VERSION ""

NS_ :

BS_:

BU_: VCU BMS CCU Monitor

BO_ 3221225472 VECTOR__INDEPENDENT_SIG_MSG: 0 Vector__XXX
 SG_ CCU2_1_Rsvd2 : 0|1@0+ (1,0) [0|1] "" Vector__XXX
 SG_ CCU2_2_Rsvd2 : 0|1@0+ (1,0) [0|1] "" Vector__XXX
 SG_ CCU2_0_Rsvd2 : 0|1@0+ (1,0) [0|1] "" Vector__XXX
 SG_ CCU2_3_Rsvd2 : 0|1@0+ (1,0) [0|1] "" Vector__XXX

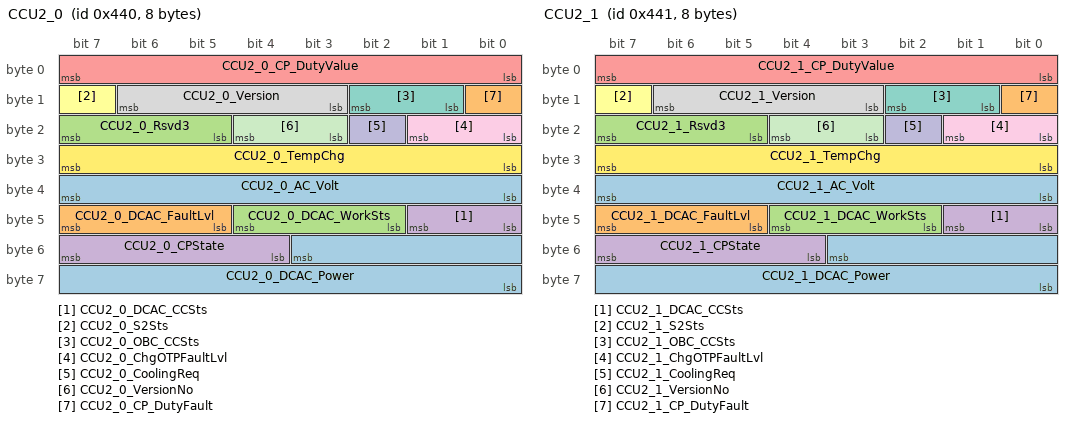
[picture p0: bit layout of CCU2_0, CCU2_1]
BO_ 1088 CCU2_0: 8 CCU
 SG_ CCU2_0_DCAC_Power : 51|12@0+ (1,0) [0|2047] "W"  BMS
 SG_ CCU2_0_DCAC_FaultLvl : 47|3@0+ (1,0) [0|3] ""  BMS
 SG_ CCU2_0_DCAC_WorkSts : 44|3@0+ (1,0) [0|7] ""  BMS
 SG_ CCU2_0_DCAC_CCSts : 41|2@0+ (1,0) [0|3] ""  BMS
 SG_ CCU2_0_CP_DutyValue : 7|8@0+ (1,0) [0|100] ""  BMS
 SG_ CCU2_0_S2Sts : 15|1@0+ (1,0) [0|1] ""  BMS
 SG_ CCU2_0_OBC_CCSts : 10|2@0+ (1,0) [0|3] ""  BMS
 SG_ CCU2_0_Version : 14|4@0+ (1,0) [0|3] ""  BMS
 SG_ CCU2_0_ChgOTPFaultLvl : 17|2@0+ (1,0) [0|3] ""  BMS
 SG_ CCU2_0_CoolingReq : 18|1@0+ (1,0) [0|1] ""  BMS
 SG_ CCU2_0_VersionNo : 20|2@0+ (1,0) [0|3] ""  BMS
 SG_ CCU2_0_TempChg : 31|8@0+ (1,-40) [-40|215] "C"  BMS
 SG_ CCU2_0_AC_Volt : 39|8@0+ (2,0) [0|510] "V"  BMS
 SG_ CCU2_0_CP_DutyFault : 8|1@0+ (1,0) [0|1] ""  BMS
 SG_ CCU2_0_Rsvd3 : 23|3@0+ (1,0) [0|7] ""  BMS
 SG_ CCU2_0_CPState : 55|4@0+ (1,0) [0|0] ""  BMS

BO_ 1089 CCU2_1: 8 CCU
 SG_ CCU2_1_DCAC_Power : 51|12@0+ (1,0) [0|2047] "W"  BMS
 SG_ CCU2_1_DCAC_FaultLvl : 47|3@0+ (1,0) [0|3] ""  BMS
 SG_ CCU2_1_DCAC_WorkSts : 44|3@0+ (1,0) [0|7] ""  BMS
 SG_ CCU2_1_DCAC_CCSts : 41|2@0+ (1,0) [0|3] ""  BMS
 SG_ CCU2_1_CP_DutyValue : 7|8@0+ (1,0) [0|100] ""  BMS
 SG_ CCU2_1_S2Sts : 15|1@0+ (1,0) [0|1] ""  BMS
 SG_ CCU2_1_OBC_CCSts : 10|2@0+ (1,0) [0|3] ""  BMS
 SG_ CCU2_1_Version : 14|4@0+ (1,0) [0|3] ""  BMS
 SG_ CCU2_1_ChgOTPFaultLvl : 17|2@0+ (1,0) [0|3] ""  BMS
 SG_ CCU2_1_CoolingReq : 18|1@0+ (1,0) [0|1] ""  BMS
 SG_ CCU2_1_VersionNo : 20|2@0+ (1,0) [0|3] ""  BMS
 SG_ CCU2_1_TempChg : 31|8@0+ (1,-40) [-40|215] "C"  BMS
 SG_ CCU2_1_AC_Volt : 39|8@0+ (2,0) [0|510] "V"  BMS
 SG_ CCU2_1_CP_DutyFault : 8|1@0+ (1,0) [0|1] ""  BMS
 SG_ CCU2_1_Rsvd3 : 23|3@0+ (1,0) [0|7] ""  BMS
 SG_ CCU2_1_CPState : 55|4@0+ (1,0) [0|0] ""  BMS

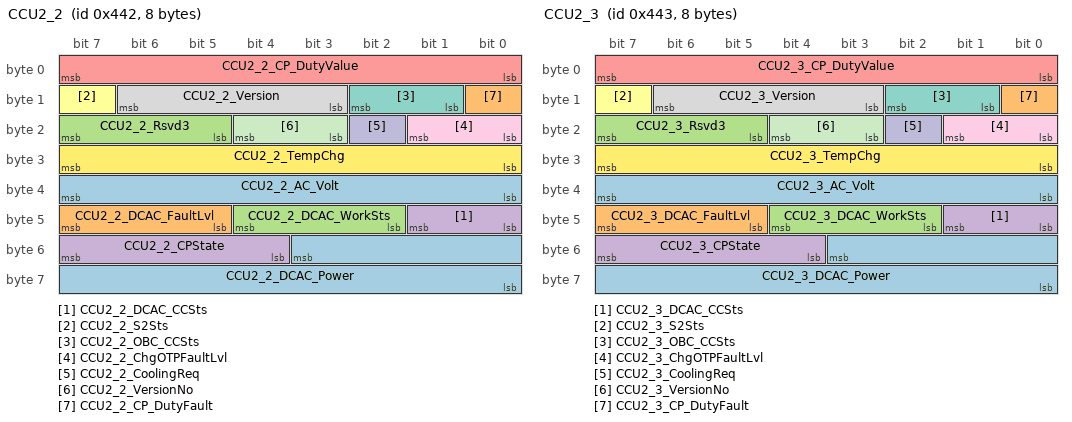
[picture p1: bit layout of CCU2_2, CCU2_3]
BO_ 1090 CCU2_2: 8 CCU
 SG_ CCU2_2_DCAC_Power : 51|12@0+ (1,0) [0|2047] "W"  BMS
 SG_ CCU2_2_DCAC_FaultLvl : 47|3@0+ (1,0) [0|3] ""  BMS
 SG_ CCU2_2_DCAC_WorkSts : 44|3@0+ (1,0) [0|7] ""  BMS
 SG_ CCU2_2_DCAC_CCSts : 41|2@0+ (1,0) [0|3] ""  BMS
 SG_ CCU2_2_CP_DutyValue : 7|8@0+ (1,0) [0|100] ""  BMS
 SG_ CCU2_2_S2Sts : 15|1@0+ (1,0) [0|1] ""  BMS
 SG_ CCU2_2_OBC_CCSts : 10|2@0+ (1,0) [0|3] ""  BMS
 SG_ CCU2_2_Version : 14|4@0+ (1,0) [0|3] ""  BMS
 SG_ CCU2_2_ChgOTPFaultLvl : 17|2@0+ (1,0) [0|3] ""  BMS
 SG_ CCU2_2_CoolingReq : 18|1@0+ (1,0) [0|1] ""  BMS
 SG_ CCU2_2_VersionNo : 20|2@0+ (1,0) [0|3] ""  BMS
 SG_ CCU2_2_TempChg : 31|8@0+ (1,-40) [-40|215] "C"  BMS
 SG_ CCU2_2_AC_Volt : 39|8@0+ (2,0) [0|510] "V"  BMS
 SG_ CCU2_2_CP_DutyFault : 8|1@0+ (1,0) [0|1] ""  BMS
 SG_ CCU2_2_Rsvd3 : 23|3@0+ (1,0) [0|7] ""  BMS
 SG_ CCU2_2_CPState : 55|4@0+ (1,0) [0|0] ""  BMS

BO_ 1091 CCU2_3: 8 CCU
 SG_ CCU2_3_DCAC_Power : 51|12@0+ (1,0) [0|2047] "W"  BMS
 SG_ CCU2_3_DCAC_FaultLvl : 47|3@0+ (1,0) [0|3] ""  BMS
 SG_ CCU2_3_DCAC_WorkSts : 44|3@0+ (1,0) [0|7] ""  BMS
 SG_ CCU2_3_DCAC_CCSts : 41|2@0+ (1,0) [0|3] ""  BMS
 SG_ CCU2_3_CP_DutyValue : 7|8@0+ (1,0) [0|100] ""  BMS
 SG_ CCU2_3_S2Sts : 15|1@0+ (1,0) [0|1] ""  BMS
 SG_ CCU2_3_OBC_CCSts : 10|2@0+ (1,0) [0|3] ""  BMS
 SG_ CCU2_3_Version : 14|4@0+ (1,0) [0|3] ""  BMS
 SG_ CCU2_3_ChgOTPFaultLvl : 17|2@0+ (1,0) [0|3] ""  BMS
 SG_ CCU2_3_CoolingReq : 18|1@0+ (1,0) [0|1] ""  BMS
 SG_ CCU2_3_VersionNo : 20|2@0+ (1,0) [0|3] ""  BMS
 SG_ CCU2_3_TempChg : 31|8@0+ (1,-40) [-40|215] "C"  BMS
 SG_ CCU2_3_AC_Volt : 39|8@0+ (2,0) [0|510] "V"  BMS
 SG_ CCU2_3_CP_DutyFault : 8|1@0+ (1,0) [0|1] ""  BMS
 SG_ CCU2_3_Rsvd3 : 23|3@0+ (1,0) [0|7] ""  BMS
 SG_ CCU2_3_CPState : 55|4@0+ (1,0) [0|0] ""  BMS

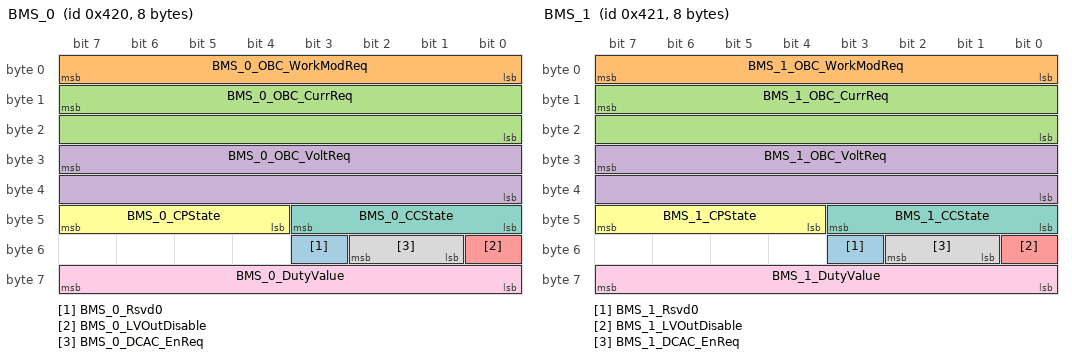
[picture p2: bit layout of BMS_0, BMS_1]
BO_ 1056 BMS_0: 8 BMS
 SG_ BMS_0_Rsvd0 : 51|1@0+ (1,0) [0|1] ""  CCU
 SG_ BMS_0_OBC_WorkModReq : 7|8@0+ (1,0) [0|4] ""  CCU
 SG_ BMS_0_OBC_CurrReq : 15|16@0+ (0.05,0) [0|400] "A"  CCU
 SG_ BMS_0_OBC_VoltReq : 31|16@0+ (0.05,0) [0|1000] "V"  CCU
 SG_ BMS_0_LVOutDisable : 48|1@0+ (1,0) [0|1] ""  CCU
 SG_ BMS_0_CPState : 47|4@0+ (1,0) [0|0] ""  CCU
 SG_ BMS_0_CCState : 43|4@0+ (1,0) [0|0] ""  CCU
 SG_ BMS_0_DCAC_EnReq : 50|2@0+ (1,0) [0|3] ""  CCU
 SG_ BMS_0_DutyValue : 63|8@0+ (1,0) [0|100] "" Vector__XXX

BO_ 1057 BMS_1: 8 BMS
 SG_ BMS_1_Rsvd0 : 51|1@0+ (1,0) [0|1] ""  CCU
 SG_ BMS_1_OBC_WorkModReq : 7|8@0+ (1,0) [0|4] ""  CCU
 SG_ BMS_1_OBC_CurrReq : 15|16@0+ (0.05,0) [0|400] "A"  CCU
 SG_ BMS_1_OBC_VoltReq : 31|16@0+ (0.05,0) [0|1000] "V"  CCU
 SG_ BMS_1_LVOutDisable : 48|1@0+ (1,0) [0|1] ""  CCU
 SG_ BMS_1_CPState : 47|4@0+ (1,0) [0|0] ""  CCU
 SG_ BMS_1_CCState : 43|4@0+ (1,0) [0|0] ""  CCU
 SG_ BMS_1_DCAC_EnReq : 50|2@0+ (1,0) [0|3] ""  CCU
 SG_ BMS_1_DutyValue : 63|8@0+ (1,0) [0|100] "" Vector__XXX

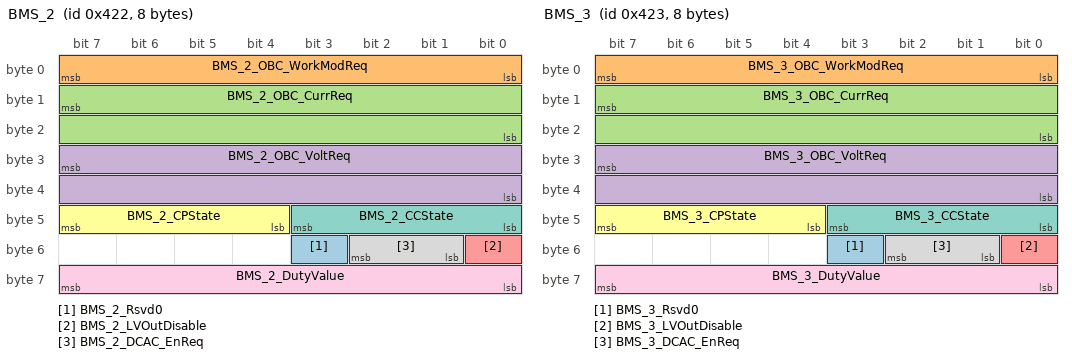
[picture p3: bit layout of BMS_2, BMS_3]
BO_ 1058 BMS_2: 8 BMS
 SG_ BMS_2_Rsvd0 : 51|1@0+ (1,0) [0|1] ""  CCU
 SG_ BMS_2_OBC_WorkModReq : 7|8@0+ (1,0) [0|4] ""  CCU
 SG_ BMS_2_OBC_CurrReq : 15|16@0+ (0.05,0) [0|400] "A"  CCU
 SG_ BMS_2_OBC_VoltReq : 31|16@0+ (0.05,0) [0|1000] "V"  CCU
 SG_ BMS_2_LVOutDisable : 48|1@0+ (1,0) [0|1] ""  CCU
 SG_ BMS_2_CPState : 47|4@0+ (1,0) [0|0] ""  CCU
 SG_ BMS_2_CCState : 43|4@0+ (1,0) [0|0] ""  CCU
 SG_ BMS_2_DCAC_EnReq : 50|2@0+ (1,0) [0|3] ""  CCU
 SG_ BMS_2_DutyValue : 63|8@0+ (1,0) [0|100] "" Vector__XXX

BO_ 1059 BMS_3: 8 BMS
 SG_ BMS_3_Rsvd0 : 51|1@0+ (1,0) [0|1] ""  CCU
 SG_ BMS_3_OBC_WorkModReq : 7|8@0+ (1,0) [0|4] ""  CCU
 SG_ BMS_3_OBC_CurrReq : 15|16@0+ (0.05,0) [0|400] "A"  CCU
 SG_ BMS_3_OBC_VoltReq : 31|16@0+ (0.05,0) [0|1000] "V"  CCU
 SG_ BMS_3_LVOutDisable : 48|1@0+ (1,0) [0|1] ""  CCU
 SG_ BMS_3_CPState : 47|4@0+ (1,0) [0|0] ""  CCU
 SG_ BMS_3_CCState : 43|4@0+ (1,0) [0|0] ""  CCU
 SG_ BMS_3_DCAC_EnReq : 50|2@0+ (1,0) [0|3] ""  CCU
 SG_ BMS_3_DutyValue : 63|8@0+ (1,0) [0|100] "" Vector__XXX

BO_ 1104 CCU3_0: 8 CCU
 SG_ CCU3_0_DCDC_OutputVolt : 7|8@0+ (0.1,0) [0|25.4] "V"  VCU
 SG_ CCU3_0_DCDC_OutputCurr : 15|8@0+ (1,0) [0|254] "A"  VCU
 SG_ CCU3_0_DCDC_InputVolt : 16|9@0+ (1,0) [0|510] "V"  VCU
 SG_ CCU3_0_DCDC_Temp : 39|8@0+ (1,-40) [-40|200] "oC"  VCU
 SG_ CCU3_0_DCDC_WorkSts : 41|2@0+ (1,0) [0|3] ""  VCU
 SG_ CCU3_0_DCDC_EnSts : 42|1@0+ (1,0) [0|1] ""  VCU
 SG_ CCU3_0_DCDC_DTC : 63|8@0+ (1,0) [0|255] ""  VCU
 SG_ CCU3_0_RollCnt : 46|4@0+ (1,0) [0|15] ""  VCU
 SG_ CCU3_0_DCDC_LVOVP : 48|1@0+ (1,0) [0|1] ""  VCU
 SG_ CCU3_0_DCDC_LVUVP : 49|1@0+ (1,0) [0|1] ""  VCU
 SG_ CCU3_0_DCDC_OTP : 50|1@0+ (1,0) [0|1] ""  VCU
 SG_ CCU3_0_DCDC_LVOCP : 51|1@0+ (1,0) [0|1] ""  VCU
 SG_ CCU3_0_DCDC_HVOVP : 52|1@0+ (1,0) [0|1] ""  VCU
 SG_ CCU3_0_DCDC_HVUVP : 53|1@0+ (1,0) [0|1] ""  VCU
 SG_ CCU3_0_DCDC_CANTimeOut : 54|1@0+ (1,0) [0|1] ""  VCU
 SG_ CCU3_0_DCDC_CoolRqt : 47|1@0+ (1,0) [0|1] ""  VCU
 SG_ CCU3_0_DCDC_ConvMode : 23|2@0+ (1,0) [0|3] ""  VCU

BO_ 1105 CCU3_1: 8 CCU
 SG_ CCU3_1_DCDC_OutputVolt : 7|8@0+ (0.1,0) [0|25.4] "V"  VCU
 SG_ CCU3_1_DCDC_OutputCurr : 15|8@0+ (1,0) [0|254] "A"  VCU
 SG_ CCU3_1_DCDC_InputVolt : 16|9@0+ (1,0) [0|510] "V"  VCU
 SG_ CCU3_1_DCDC_Temp : 39|8@0+ (1,-40) [-40|200] "oC"  VCU
 SG_ CCU3_1_DCDC_WorkSts : 41|2@0+ (1,0) [0|3] ""  VCU
 SG_ CCU3_1_DCDC_EnSts : 42|1@0+ (1,0) [0|1] ""  VCU
 SG_ CCU3_1_DCDC_DTC : 63|8@0+ (1,0) [0|255] ""  VCU
 SG_ CCU3_1_RollCnt : 46|4@0+ (1,0) [0|15] ""  VCU
 SG_ CCU3_1_DCDC_LVOVP : 48|1@0+ (1,0) [0|1] ""  VCU
 SG_ CCU3_1_DCDC_LVUVP : 49|1@0+ (1,0) [0|1] ""  VCU
 SG_ CCU3_1_DCDC_OTP : 50|1@0+ (1,0) [0|1] ""  VCU
 SG_ CCU3_1_DCDC_LVOCP : 51|1@0+ (1,0) [0|1] ""  VCU
 SG_ CCU3_1_DCDC_HVOVP : 52|1@0+ (1,0) [0|1] ""  VCU
 SG_ CCU3_1_DCDC_HVUVP : 53|1@0+ (1,0) [0|1] ""  VCU
 SG_ CCU3_1_DCDC_CANTimeOut : 54|1@0+ (1,0) [0|1] ""  VCU
 SG_ CCU3_1_DCDC_CoolRqt : 47|1@0+ (1,0) [0|1] ""  VCU
 SG_ CCU3_1_DCDC_ConvMode : 23|2@0+ (1,0) [0|3] ""  VCU

BO_ 1106 CCU3_2: 8 CCU
 SG_ CCU3_2_DCDC_OutputVolt : 7|8@0+ (0.1,0) [0|25.4] "V"  VCU
 SG_ CCU3_2_DCDC_OutputCurr : 15|8@0+ (1,0) [0|254] "A"  VCU
 SG_ CCU3_2_DCDC_InputVolt : 16|9@0+ (1,0) [0|510] "V"  VCU
 SG_ CCU3_2_DCDC_Temp : 39|8@0+ (1,-40) [-40|200] "oC"  VCU
 SG_ CCU3_2_DCDC_WorkSts : 41|2@0+ (1,0) [0|3] ""  VCU
 SG_ CCU3_2_DCDC_EnSts : 42|1@0+ (1,0) [0|1] ""  VCU
 SG_ CCU3_2_DCDC_DTC : 63|8@0+ (1,0) [0|255] ""  VCU
 SG_ CCU3_2_RollCnt : 46|4@0+ (1,0) [0|15] ""  VCU
 SG_ CCU3_2_DCDC_LVOVP : 48|1@0+ (1,0) [0|1] ""  VCU
 SG_ CCU3_2_DCDC_LVUVP : 49|1@0+ (1,0) [0|1] ""  VCU
 SG_ CCU3_2_DCDC_OTP : 50|1@0+ (1,0) [0|1] ""  VCU
 SG_ CCU3_2_DCDC_LVOCP : 51|1@0+ (1,0) [0|1] ""  VCU
 SG_ CCU3_2_DCDC_HVOVP : 52|1@0+ (1,0) [0|1] ""  VCU
 SG_ CCU3_2_DCDC_HVUVP : 53|1@0+ (1,0) [0|1] ""  VCU
 SG_ CCU3_2_DCDC_CANTimeOut : 54|1@0+ (1,0) [0|1] ""  VCU
 SG_ CCU3_2_DCDC_CoolRqt : 47|1@0+ (1,0) [0|1] ""  VCU
 SG_ CCU3_2_DCDC_ConvMode : 23|2@0+ (1,0) [0|3] ""  VCU

BO_ 1107 CCU3_3: 8 CCU
 SG_ CCU3_3_DCDC_OutputVolt : 7|8@0+ (0.1,0) [0|25.4] "V"  VCU
 SG_ CCU3_3_DCDC_OutputCurr : 15|8@0+ (1,0) [0|254] "A"  VCU
 SG_ CCU3_3_DCDC_InputVolt : 16|9@0+ (1,0) [0|510] "V"  VCU
 SG_ CCU3_3_DCDC_Temp : 39|8@0+ (1,-40) [-40|200] "oC"  VCU
 SG_ CCU3_3_DCDC_WorkSts : 41|2@0+ (1,0) [0|3] ""  VCU
 SG_ CCU3_3_DCDC_EnSts : 42|1@0+ (1,0) [0|1] ""  VCU
 SG_ CCU3_3_DCDC_DTC : 63|8@0+ (1,0) [0|255] ""  VCU
 SG_ CCU3_3_RollCnt : 46|4@0+ (1,0) [0|15] ""  VCU
 SG_ CCU3_3_DCDC_LVOVP : 48|1@0+ (1,0) [0|1] ""  VCU
 SG_ CCU3_3_DCDC_LVUVP : 49|1@0+ (1,0) [0|1] ""  VCU
 SG_ CCU3_3_DCDC_OTP : 50|1@0+ (1,0) [0|1] ""  VCU
 SG_ CCU3_3_DCDC_LVOCP : 51|1@0+ (1,0) [0|1] ""  VCU
 SG_ CCU3_3_DCDC_HVOVP : 52|1@0+ (1,0) [0|1] ""  VCU
 SG_ CCU3_3_DCDC_HVUVP : 53|1@0+ (1,0) [0|1] ""  VCU
 SG_ CCU3_3_DCDC_CANTimeOut : 54|1@0+ (1,0) [0|1] ""  VCU
 SG_ CCU3_3_DCDC_CoolRqt : 47|1@0+ (1,0) [0|1] ""  VCU
 SG_ CCU3_3_DCDC_ConvMode : 23|2@0+ (1,0) [0|3] ""  VCU

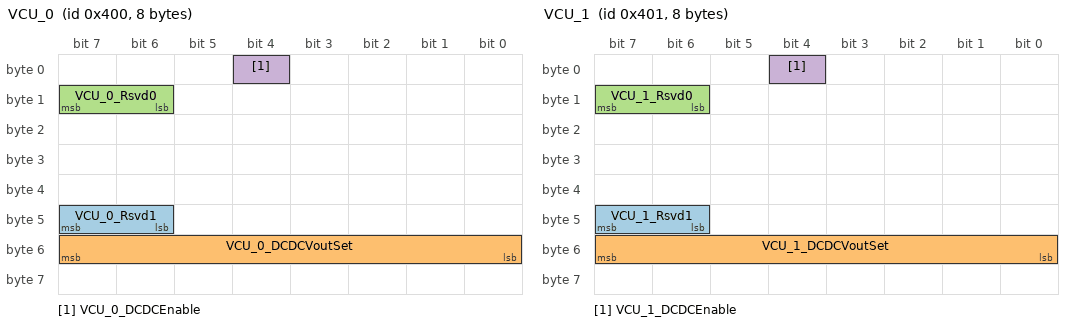
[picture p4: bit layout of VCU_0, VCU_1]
BO_ 1024 VCU_0: 8 VCU
 SG_ VCU_0_Rsvd1 : 47|2@0+ (1,0) [0|3] ""  CCU
 SG_ VCU_0_DCDCVoutSet : 55|8@0+ (0.1,0) [0|20] "V"  CCU
 SG_ VCU_0_Rsvd0 : 15|2@0+ (1,0) [0|1] ""  CCU
 SG_ VCU_0_DCDCEnable : 4|1@0+ (1,0) [0|1] ""  CCU

BO_ 1025 VCU_1: 8 VCU
 SG_ VCU_1_Rsvd1 : 47|2@0+ (1,0) [0|3] ""  CCU
 SG_ VCU_1_DCDCVoutSet : 55|8@0+ (0.1,0) [0|20] "V"  CCU
 SG_ VCU_1_Rsvd0 : 15|2@0+ (1,0) [0|1] ""  CCU
 SG_ VCU_1_DCDCEnable : 4|1@0+ (1,0) [0|1] ""  CCU

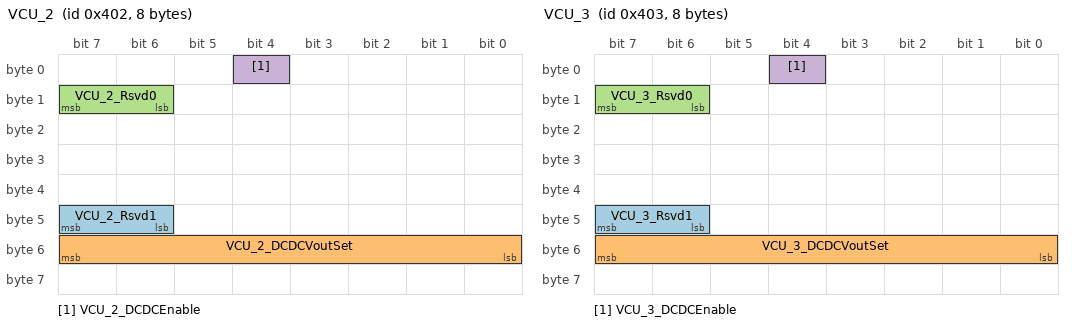
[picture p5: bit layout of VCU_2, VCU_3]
BO_ 1026 VCU_2: 8 VCU
 SG_ VCU_2_Rsvd1 : 47|2@0+ (1,0) [0|3] ""  CCU
 SG_ VCU_2_DCDCVoutSet : 55|8@0+ (0.1,0) [0|20] "V"  CCU
 SG_ VCU_2_Rsvd0 : 15|2@0+ (1,0) [0|1] ""  CCU
 SG_ VCU_2_DCDCEnable : 4|1@0+ (1,0) [0|1] ""  CCU

BO_ 1027 VCU_3: 8 VCU
 SG_ VCU_3_Rsvd1 : 47|2@0+ (1,0) [0|3] ""  CCU
 SG_ VCU_3_DCDCVoutSet : 55|8@0+ (0.1,0) [0|20] "V"  CCU
 SG_ VCU_3_Rsvd0 : 15|2@0+ (1,0) [0|1] ""  CCU
 SG_ VCU_3_DCDCEnable : 4|1@0+ (1,0) [0|1] ""  CCU

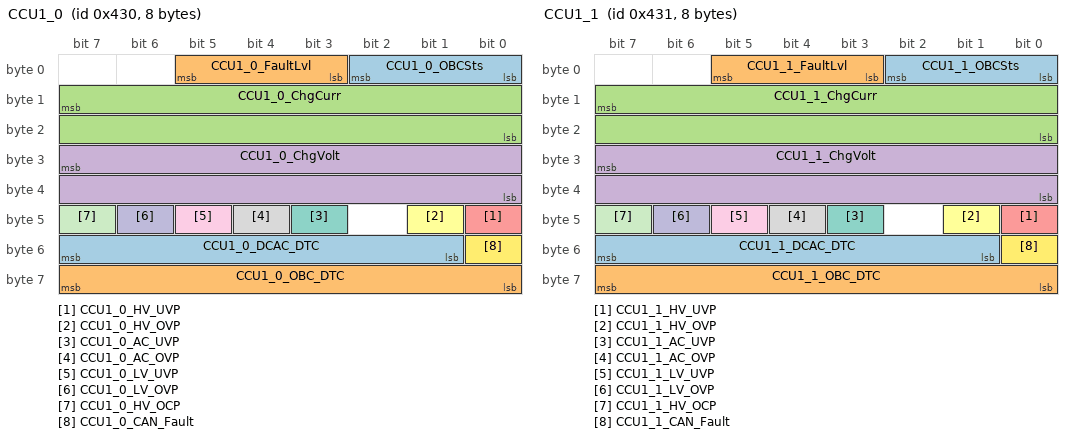
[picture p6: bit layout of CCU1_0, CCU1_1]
BO_ 1072 CCU1_0: 8 CCU
 SG_ CCU1_0_OBCSts : 2|3@0+ (1,0) [0|7] ""  BMS
 SG_ CCU1_0_FaultLvl : 5|3@0+ (1,0) [0|7] ""  BMS
 SG_ CCU1_0_ChgCurr : 15|16@0+ (0.05,0) [0|400] "A"  BMS
 SG_ CCU1_0_ChgVolt : 31|16@0+ (0.05,0) [0|1000] "V"  BMS
 SG_ CCU1_0_HV_UVP : 40|1@0+ (1,0) [0|1] ""  BMS
 SG_ CCU1_0_HV_OVP : 41|1@0+ (1,0) [0|1] ""  BMS
 SG_ CCU1_0_AC_UVP : 43|1@0+ (1,0) [0|1] ""  BMS
 SG_ CCU1_0_AC_OVP : 44|1@0+ (1,0) [0|1] ""  BMS
 SG_ CCU1_0_LV_UVP : 45|1@0+ (1,0) [0|1] ""  BMS
 SG_ CCU1_0_LV_OVP : 46|1@0+ (1,0) [0|1] ""  BMS
 SG_ CCU1_0_HV_OCP : 47|1@0+ (1,0) [0|1] ""  BMS
 SG_ CCU1_0_CAN_Fault : 48|1@0+ (1,0) [0|1] ""  BMS
 SG_ CCU1_0_DCAC_DTC : 55|7@0+ (1,0) [0|1] ""  BMS
 SG_ CCU1_0_OBC_DTC : 63|8@0+ (1,0) [0|0] ""  BMS

BO_ 1073 CCU1_1: 8 CCU
 SG_ CCU1_1_OBCSts : 2|3@0+ (1,0) [0|7] ""  BMS
 SG_ CCU1_1_FaultLvl : 5|3@0+ (1,0) [0|7] ""  BMS
 SG_ CCU1_1_ChgCurr : 15|16@0+ (0.05,0) [0|400] "A"  BMS
 SG_ CCU1_1_ChgVolt : 31|16@0+ (0.05,0) [0|1000] "V"  BMS
 SG_ CCU1_1_HV_UVP : 40|1@0+ (1,0) [0|1] ""  BMS
 SG_ CCU1_1_HV_OVP : 41|1@0+ (1,0) [0|1] ""  BMS
 SG_ CCU1_1_AC_UVP : 43|1@0+ (1,0) [0|1] ""  BMS
 SG_ CCU1_1_AC_OVP : 44|1@0+ (1,0) [0|1] ""  BMS
 SG_ CCU1_1_LV_UVP : 45|1@0+ (1,0) [0|1] ""  BMS
 SG_ CCU1_1_LV_OVP : 46|1@0+ (1,0) [0|1] ""  BMS
 SG_ CCU1_1_HV_OCP : 47|1@0+ (1,0) [0|1] ""  BMS
 SG_ CCU1_1_CAN_Fault : 48|1@0+ (1,0) [0|1] ""  BMS
 SG_ CCU1_1_DCAC_DTC : 55|7@0+ (1,0) [0|1] ""  BMS
 SG_ CCU1_1_OBC_DTC : 63|8@0+ (1,0) [0|0] ""  BMS

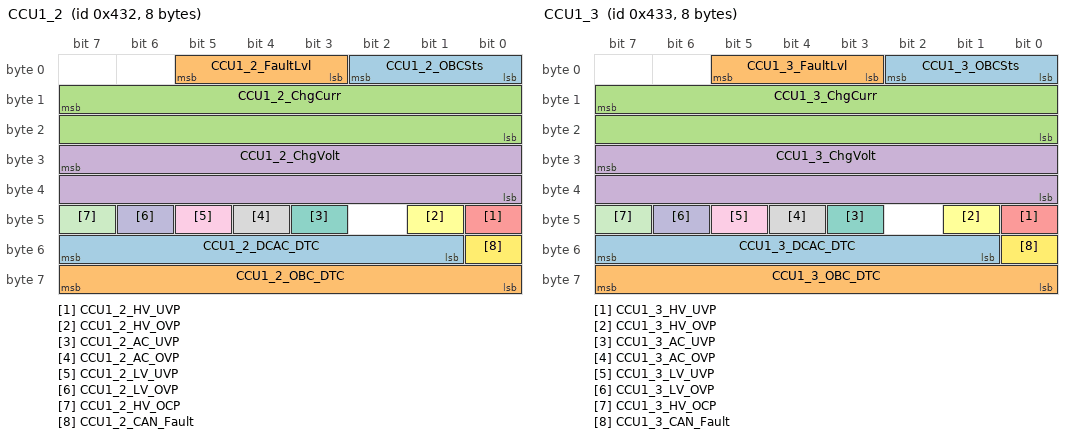
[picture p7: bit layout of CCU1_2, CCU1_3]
BO_ 1074 CCU1_2: 8 CCU
 SG_ CCU1_2_OBCSts : 2|3@0+ (1,0) [0|7] ""  BMS
 SG_ CCU1_2_FaultLvl : 5|3@0+ (1,0) [0|7] ""  BMS
 SG_ CCU1_2_ChgCurr : 15|16@0+ (0.05,0) [0|400] "A"  BMS
 SG_ CCU1_2_ChgVolt : 31|16@0+ (0.05,0) [0|1000] "V"  BMS
 SG_ CCU1_2_HV_UVP : 40|1@0+ (1,0) [0|1] ""  BMS
 SG_ CCU1_2_HV_OVP : 41|1@0+ (1,0) [0|1] ""  BMS
 SG_ CCU1_2_AC_UVP : 43|1@0+ (1,0) [0|1] ""  BMS
 SG_ CCU1_2_AC_OVP : 44|1@0+ (1,0) [0|1] ""  BMS
 SG_ CCU1_2_LV_UVP : 45|1@0+ (1,0) [0|1] ""  BMS
 SG_ CCU1_2_LV_OVP : 46|1@0+ (1,0) [0|1] ""  BMS
 SG_ CCU1_2_HV_OCP : 47|1@0+ (1,0) [0|1] ""  BMS
 SG_ CCU1_2_CAN_Fault : 48|1@0+ (1,0) [0|1] ""  BMS
 SG_ CCU1_2_DCAC_DTC : 55|7@0+ (1,0) [0|1] ""  BMS
 SG_ CCU1_2_OBC_DTC : 63|8@0+ (1,0) [0|0] ""  BMS

BO_ 1075 CCU1_3: 8 CCU
 SG_ CCU1_3_OBCSts : 2|3@0+ (1,0) [0|7] ""  BMS
 SG_ CCU1_3_FaultLvl : 5|3@0+ (1,0) [0|7] ""  BMS
 SG_ CCU1_3_ChgCurr : 15|16@0+ (0.05,0) [0|400] "A"  BMS
 SG_ CCU1_3_ChgVolt : 31|16@0+ (0.05,0) [0|1000] "V"  BMS
 SG_ CCU1_3_HV_UVP : 40|1@0+ (1,0) [0|1] ""  BMS
 SG_ CCU1_3_HV_OVP : 41|1@0+ (1,0) [0|1] ""  BMS
 SG_ CCU1_3_AC_UVP : 43|1@0+ (1,0) [0|1] ""  BMS
 SG_ CCU1_3_AC_OVP : 44|1@0+ (1,0) [0|1] ""  BMS
 SG_ CCU1_3_LV_UVP : 45|1@0+ (1,0) [0|1] ""  BMS
 SG_ CCU1_3_LV_OVP : 46|1@0+ (1,0) [0|1] ""  BMS
 SG_ CCU1_3_HV_OCP : 47|1@0+ (1,0) [0|1] ""  BMS
 SG_ CCU1_3_CAN_Fault : 48|1@0+ (1,0) [0|1] ""  BMS
 SG_ CCU1_3_DCAC_DTC : 55|7@0+ (1,0) [0|1] ""  BMS
 SG_ CCU1_3_OBC_DTC : 63|8@0+ (1,0) [0|0] ""  BMS

BO_ 1280 CaliIDTX_0: 8 Monitor
 SG_ CaliIDTX_0 : 7|64@0+ (1,0) [0|0] ""  CCU

BO_ 1281 CaliIDTX_1: 8 Monitor
 SG_ CaliIDTX_1 : 7|64@0+ (1,0) [0|0] ""  CCU

BO_ 1282 CaliIDTX_2: 8 Monitor
 SG_ CaliIDTX_2 : 7|64@0+ (1,0) [0|0] ""  CCU

BO_ 1283 CaliIDTX_3: 8 Monitor
 SG_ CaliIDTX_3 : 7|64@0+ (1,0) [0|0] ""  CCU

BO_ 1296 CaliIDRX: 8 CCU
 SG_ CaliIDR_0 : 7|64@0+ (1,0) [0|0] ""  Monitor

BO_ 1297 CaliIDRX: 8 CCU
 SG_ CaliIDRX_1 : 7|64@0+ (1,0) [0|0] ""  Monitor

BO_ 1298 CaliIDRX: 8 CCU
 SG_ CaliIDRX_2 : 7|64@0+ (1,0) [0|0] ""  Monitor

BO_ 1299 CaliIDRX: 8 CCU
 SG_ CaliIDRX_3 : 7|64@0+ (1,0) [0|0] ""  Monitor

CM_ BO_ 3221225472 "This is a message for not used signals, created by Vector CANdb++ DBC OLE DB Provider.";
CM_ SG_ 3221225472 CCU2_1_Rsvd2 "保留
(Reserved)";
CM_ SG_ 3221225472 CCU2_2_Rsvd2 "保留
(Reserved)";
CM_ SG_ 3221225472 CCU2_0_Rsvd2 "保留
(Reserved)";
CM_ SG_ 3221225472 CCU2_3_Rsvd2 "保留
(Reserved)";
CM_ SG_ 1088 CCU2_0_DCAC_Power "DCAC输出功率
(DCAC output power)";
CM_ SG_ 1088 CCU2_0_DCAC_FaultLvl "DCAC故障等级
(DCAC fault level)";
CM_ SG_ 1088 CCU2_0_DCAC_WorkSts "DCAC工作状态
(DCAC work status)";
CM_ SG_ 1088 CCU2_0_DCAC_CCSts "放电CC连接状态
(CC connect status in DCAC mode)";
CM_ SG_ 1088 CCU2_0_CP_DutyValue "CP占空比数值
(CP duty value)";
CM_ SG_ 1088 CCU2_0_S2Sts "S2开关状态
(S2 switch status)";
CM_ SG_ 1088 CCU2_0_OBC_CCSts "充电CC连接状态
(CC connect status in OBC mode)";
CM_ SG_ 1088 CCU2_0_ChgOTPFaultLvl "充电机过温
(Charge over temperature protection)";
CM_ SG_ 1088 CCU2_0_CoolingReq "充电机冷却请求
(Charger cool request)";
CM_ SG_ 1088 CCU2_0_VersionNo "软件版本序号
（Version No）";
CM_ SG_ 1088 CCU2_0_TempChg "充电机温度
(Charger temperature)";
CM_ SG_ 1088 CCU2_0_AC_Volt "AC电压(AC Volt)";
CM_ SG_ 1088 CCU2_0_CP_DutyFault "CP占空比异常
(CP duty abnormal)";
CM_ SG_ 1088 CCU2_0_CPState "CP状态
(CP state)";
CM_ SG_ 1089 CCU2_1_DCAC_Power "DCAC输出功率
(DCAC output power)";
CM_ SG_ 1089 CCU2_1_DCAC_FaultLvl "DCAC故障等级
(DCAC fault level)";
CM_ SG_ 1089 CCU2_1_DCAC_WorkSts "DCAC工作状态
(DCAC work status)";
CM_ SG_ 1089 CCU2_1_DCAC_CCSts "放电CC连接状态
(CC connect status in DCAC mode)";
CM_ SG_ 1089 CCU2_1_CP_DutyValue "CP占空比数值
(CP duty value)";
CM_ SG_ 1089 CCU2_1_S2Sts "S2开关状态
(S2 switch status)";
CM_ SG_ 1089 CCU2_1_OBC_CCSts "充电CC连接状态
(CC connect status in OBC mode)";
CM_ SG_ 1089 CCU2_1_ChgOTPFaultLvl "充电机过温
(Charge over temperature protection)";
CM_ SG_ 1089 CCU2_1_CoolingReq "充电机冷却请求
(Charger cool request)";
CM_ SG_ 1089 CCU2_1_VersionNo "软件版本序号
（Version No）";
CM_ SG_ 1089 CCU2_1_TempChg "充电机温度
(Charger temperature)";
CM_ SG_ 1089 CCU2_1_AC_Volt "AC电压(AC Volt)";
CM_ SG_ 1089 CCU2_1_CP_DutyFault "CP占空比异常
(CP duty abnormal)";
CM_ SG_ 1089 CCU2_1_CPState "CP状态
(CP state)";
CM_ SG_ 1090 CCU2_2_DCAC_Power "DCAC输出功率
(DCAC output power)";
CM_ SG_ 1090 CCU2_2_DCAC_FaultLvl "DCAC故障等级
(DCAC fault level)";
CM_ SG_ 1090 CCU2_2_DCAC_WorkSts "DCAC工作状态
(DCAC work status)";
CM_ SG_ 1090 CCU2_2_DCAC_CCSts "放电CC连接状态
(CC connect status in DCAC mode)";
CM_ SG_ 1090 CCU2_2_CP_DutyValue "CP占空比数值
(CP duty value)";
CM_ SG_ 1090 CCU2_2_S2Sts "S2开关状态
(S2 switch status)";
CM_ SG_ 1090 CCU2_2_OBC_CCSts "充电CC连接状态
(CC connect status in OBC mode)";
CM_ SG_ 1090 CCU2_2_ChgOTPFaultLvl "充电机过温
(Charge over temperature protection)";
CM_ SG_ 1090 CCU2_2_CoolingReq "充电机冷却请求
(Charger cool request)";
CM_ SG_ 1090 CCU2_2_VersionNo "软件版本序号
（Version No）";
CM_ SG_ 1090 CCU2_2_TempChg "充电机温度
(Charger temperature)";
CM_ SG_ 1090 CCU2_2_AC_Volt "AC电压(AC Volt)";
CM_ SG_ 1090 CCU2_2_CP_DutyFault "CP占空比异常
(CP duty abnormal)";
CM_ SG_ 1090 CCU2_2_CPState "CP状态
(CP state)";
CM_ SG_ 1091 CCU2_3_DCAC_Power "DCAC输出功率
(DCAC output power)";
CM_ SG_ 1091 CCU2_3_DCAC_FaultLvl "DCAC故障等级
(DCAC fault level)";
CM_ SG_ 1091 CCU2_3_DCAC_WorkSts "DCAC工作状态
(DCAC work status)";
CM_ SG_ 1091 CCU2_3_DCAC_CCSts "放电CC连接状态
(CC connect status in DCAC mode)";
CM_ SG_ 1091 CCU2_3_CP_DutyValue "CP占空比数值
(CP duty value)";
CM_ SG_ 1091 CCU2_3_S2Sts "S2开关状态
(S2 switch status)";
CM_ SG_ 1091 CCU2_3_OBC_CCSts "充电CC连接状态
(CC connect status in OBC mode)";
CM_ SG_ 1091 CCU2_3_ChgOTPFaultLvl "充电机过温
(Charge over temperature protection)";
CM_ SG_ 1091 CCU2_3_CoolingReq "充电机冷却请求
(Charger cool request)";
CM_ SG_ 1091 CCU2_3_VersionNo "软件版本序号
（Version No）";
CM_ SG_ 1091 CCU2_3_TempChg "充电机温度
(Charger temperature)";
CM_ SG_ 1091 CCU2_3_AC_Volt "AC电压(AC Volt)";
CM_ SG_ 1091 CCU2_3_CP_DutyFault "CP占空比异常
(CP duty abnormal)";
CM_ SG_ 1091 CCU2_3_CPState "CP状态
(CP state)";
CM_ SG_ 1056 BMS_0_Rsvd0 "Reserved,all value keep 0.";
CM_ SG_ 1056 BMS_0_OBC_WorkModReq "BMS请求工作模式
(BMS request work mode)";
CM_ SG_ 1056 BMS_0_OBC_CurrReq "BMS请求充电机输出充电电流值
(OBC output current point setting)";
CM_ SG_ 1056 BMS_0_OBC_VoltReq "BMS请求充电机输出充电电压值
(OBC output voltage point setting)";
CM_ SG_ 1056 BMS_0_LVOutDisable "BMS请求低压停止输出请求
(BMS request DCDC stop output)";
CM_ SG_ 1056 BMS_0_CPState "CP状态
(CP state)";
CM_ SG_ 1056 BMS_0_CCState "CC状态
(CC state)";
CM_ SG_ 1056 BMS_0_DCAC_EnReq "BMS请求DCAC输出
(BMS enable DCAC output)";
CM_ SG_ 1056 BMS_0_DutyValue "CP占空比数值
(CP duty value)";
CM_ SG_ 1057 BMS_1_Rsvd0 "Reserved,all value keep 0.";
CM_ SG_ 1057 BMS_1_OBC_WorkModReq "BMS请求工作模式
(BMS request work mode)";
CM_ SG_ 1057 BMS_1_OBC_CurrReq "BMS请求充电机输出充电电流值
(OBC output current point setting)";
CM_ SG_ 1057 BMS_1_OBC_VoltReq "BMS请求充电机输出充电电压值
(OBC output voltage point setting)";
CM_ SG_ 1057 BMS_1_LVOutDisable "BMS请求低压停止输出请求
(BMS request DCDC stop output)";
CM_ SG_ 1057 BMS_1_CPState "CP状态
(CP state)";
CM_ SG_ 1057 BMS_1_CCState "CC状态
(CC state)";
CM_ SG_ 1057 BMS_1_DCAC_EnReq "BMS请求DCAC输出
(BMS enable DCAC output)";
CM_ SG_ 1057 BMS_1_DutyValue "CP占空比数值
(CP duty value)";
CM_ SG_ 1058 BMS_2_Rsvd0 "Reserved,all value keep 0.";
CM_ SG_ 1058 BMS_2_OBC_WorkModReq "BMS请求工作模式
(BMS request work mode)";
CM_ SG_ 1058 BMS_2_OBC_CurrReq "BMS请求充电机输出充电电流值
(OBC output current point setting)";
CM_ SG_ 1058 BMS_2_OBC_VoltReq "BMS请求充电机输出充电电压值
(OBC output voltage point setting)";
CM_ SG_ 1058 BMS_2_LVOutDisable "BMS请求低压停止输出请求
(BMS request DCDC stop output)";
CM_ SG_ 1058 BMS_2_CPState "CP状态
(CP state)";
CM_ SG_ 1058 BMS_2_CCState "CC状态
(CC state)";
CM_ SG_ 1058 BMS_2_DCAC_EnReq "BMS请求DCAC输出
(BMS enable DCAC output)";
CM_ SG_ 1058 BMS_2_DutyValue "CP占空比数值
(CP duty value)";
CM_ SG_ 1059 BMS_3_Rsvd0 "Reserved,all value keep 0.";
CM_ SG_ 1059 BMS_3_OBC_WorkModReq "BMS请求工作模式
(BMS request work mode)";
CM_ SG_ 1059 BMS_3_OBC_CurrReq "BMS请求充电机输出充电电流值
(OBC output current point setting)";
CM_ SG_ 1059 BMS_3_OBC_VoltReq "BMS请求充电机输出充电电压值
(OBC output voltage point setting)";
CM_ SG_ 1059 BMS_3_LVOutDisable "BMS请求低压停止输出请求
(BMS request DCDC stop output)";
CM_ SG_ 1059 BMS_3_CPState "CP状态
(CP state)";
CM_ SG_ 1059 BMS_3_CCState "CC状态
(CC state)";
CM_ SG_ 1059 BMS_3_DCAC_EnReq "BMS请求DCAC输出
(BMS enable DCAC output)";
CM_ SG_ 1059 BMS_3_DutyValue "CP占空比数值
(CP duty value)";
CM_ SG_ 1104 CCU3_0_DCDC_OutputVolt "DCDC输出电压
(DCDC output voltage)";
CM_ SG_ 1104 CCU3_0_DCDC_OutputCurr "DCDC输出电流
(DCDC output current)";
CM_ SG_ 1104 CCU3_0_DCDC_InputVolt "DCDC输入电压
(DCDC input voltage)";
CM_ SG_ 1104 CCU3_0_DCDC_Temp "DCDC温度
(DCDC temperature)";
CM_ SG_ 1104 CCU3_0_DCDC_WorkSts "DCDC工作状态
(DCDC work status)";
CM_ SG_ 1104 CCU3_0_DCDC_EnSts "DCDC使能状态反馈
(DCDC output enable status feedback)";
CM_ SG_ 1104 CCU3_0_DCDC_DTC "DCDC故障
(DCDC DTC)";
CM_ SG_ 1104 CCU3_0_RollCnt "Rolling counter.";
CM_ SG_ 1104 CCU3_0_DCDC_LVOVP "DCDC输出过压
(DCDC output over voltage)";
CM_ SG_ 1104 CCU3_0_DCDC_LVUVP "DCDC输出欠压
(DCDC output under voltage)";
CM_ SG_ 1104 CCU3_0_DCDC_OTP "DCDC过温故障
(DCDC over temperature fault)";
CM_ SG_ 1104 CCU3_0_DCDC_LVOCP "DCDC输出过流
(DCDC output over current fault)";
CM_ SG_ 1104 CCU3_0_DCDC_HVOVP "DCDC输入过压
(DCDC input over voltage)";
CM_ SG_ 1104 CCU3_0_DCDC_HVUVP "DCDC输入欠压
(DCDC input under voltage)";
CM_ SG_ 1104 CCU3_0_DCDC_CANTimeOut "DCDC通讯超时
(DCDC CAN communication time-out)";
CM_ SG_ 1104 CCU3_0_DCDC_CoolRqt "DCDC冷却请求
(DCDC cool request)";
CM_ SG_ 1104 CCU3_0_DCDC_ConvMode "DCDC功率转换模式
(DCDC power conversion mode)";
CM_ SG_ 1105 CCU3_1_DCDC_OutputVolt "DCDC输出电压
(DCDC output voltage)";
CM_ SG_ 1105 CCU3_1_DCDC_OutputCurr "DCDC输出电流
(DCDC output current)";
CM_ SG_ 1105 CCU3_1_DCDC_InputVolt "DCDC输入电压
(DCDC input voltage)";
CM_ SG_ 1105 CCU3_1_DCDC_Temp "DCDC温度
(DCDC temperature)";
CM_ SG_ 1105 CCU3_1_DCDC_WorkSts "DCDC工作状态
(DCDC work status)";
CM_ SG_ 1105 CCU3_1_DCDC_EnSts "DCDC使能状态反馈
(DCDC output enable status feedback)";
CM_ SG_ 1105 CCU3_1_DCDC_DTC "DCDC故障
(DCDC DTC)";
CM_ SG_ 1105 CCU3_1_RollCnt "Rolling counter.";
CM_ SG_ 1105 CCU3_1_DCDC_LVOVP "DCDC输出过压
(DCDC output over voltage)";
CM_ SG_ 1105 CCU3_1_DCDC_LVUVP "DCDC输出欠压
(DCDC output under voltage)";
CM_ SG_ 1105 CCU3_1_DCDC_OTP "DCDC过温故障
(DCDC over temperature fault)";
CM_ SG_ 1105 CCU3_1_DCDC_LVOCP "DCDC输出过流
(DCDC output over current fault)";
CM_ SG_ 1105 CCU3_1_DCDC_HVOVP "DCDC输入过压
(DCDC input over voltage)";
CM_ SG_ 1105 CCU3_1_DCDC_HVUVP "DCDC输入欠压
(DCDC input under voltage)";
CM_ SG_ 1105 CCU3_1_DCDC_CANTimeOut "DCDC通讯超时
(DCDC CAN communication time-out)";
CM_ SG_ 1105 CCU3_1_DCDC_CoolRqt "DCDC冷却请求
(DCDC cool request)";
CM_ SG_ 1105 CCU3_1_DCDC_ConvMode "DCDC功率转换模式
(DCDC power conversion mode)";
CM_ SG_ 1106 CCU3_2_DCDC_OutputVolt "DCDC输出电压
(DCDC output voltage)";
CM_ SG_ 1106 CCU3_2_DCDC_OutputCurr "DCDC输出电流
(DCDC output current)";
CM_ SG_ 1106 CCU3_2_DCDC_InputVolt "DCDC输入电压
(DCDC input voltage)";
CM_ SG_ 1106 CCU3_2_DCDC_Temp "DCDC温度
(DCDC temperature)";
CM_ SG_ 1106 CCU3_2_DCDC_WorkSts "DCDC工作状态
(DCDC work status)";
CM_ SG_ 1106 CCU3_2_DCDC_EnSts "DCDC使能状态反馈
(DCDC output enable status feedback)";
CM_ SG_ 1106 CCU3_2_DCDC_DTC "DCDC故障
(DCDC DTC)";
CM_ SG_ 1106 CCU3_2_RollCnt "Rolling counter.";
CM_ SG_ 1106 CCU3_2_DCDC_LVOVP "DCDC输出过压
(DCDC output over voltage)";
CM_ SG_ 1106 CCU3_2_DCDC_LVUVP "DCDC输出欠压
(DCDC output under voltage)";
CM_ SG_ 1106 CCU3_2_DCDC_OTP "DCDC过温故障
(DCDC over temperature fault)";
CM_ SG_ 1106 CCU3_2_DCDC_LVOCP "DCDC输出过流
(DCDC output over current fault)";
CM_ SG_ 1106 CCU3_2_DCDC_HVOVP "DCDC输入过压
(DCDC input over voltage)";
CM_ SG_ 1106 CCU3_2_DCDC_HVUVP "DCDC输入欠压
(DCDC input under voltage)";
CM_ SG_ 1106 CCU3_2_DCDC_CANTimeOut "DCDC通讯超时
(DCDC CAN communication time-out)";
CM_ SG_ 1106 CCU3_2_DCDC_CoolRqt "DCDC冷却请求
(DCDC cool request)";
CM_ SG_ 1106 CCU3_2_DCDC_ConvMode "DCDC功率转换模式
(DCDC power conversion mode)";
CM_ SG_ 1107 CCU3_3_DCDC_OutputVolt "DCDC输出电压
(DCDC output voltage)";
CM_ SG_ 1107 CCU3_3_DCDC_OutputCurr "DCDC输出电流
(DCDC output current)";
CM_ SG_ 1107 CCU3_3_DCDC_InputVolt "DCDC输入电压
(DCDC input voltage)";
CM_ SG_ 1107 CCU3_3_DCDC_Temp "DCDC温度
(DCDC temperature)";
CM_ SG_ 1107 CCU3_3_DCDC_WorkSts "DCDC工作状态
(DCDC work status)";
CM_ SG_ 1107 CCU3_3_DCDC_EnSts "DCDC使能状态反馈
(DCDC output enable status feedback)";
CM_ SG_ 1107 CCU3_3_DCDC_DTC "DCDC故障
(DCDC DTC)";
CM_ SG_ 1107 CCU3_3_RollCnt "Rolling counter.";
CM_ SG_ 1107 CCU3_3_DCDC_LVOVP "DCDC输出过压
(DCDC output over voltage)";
CM_ SG_ 1107 CCU3_3_DCDC_LVUVP "DCDC输出欠压
(DCDC output under voltage)";
CM_ SG_ 1107 CCU3_3_DCDC_OTP "DCDC过温故障
(DCDC over temperature fault)";
CM_ SG_ 1107 CCU3_3_DCDC_LVOCP "DCDC输出过流
(DCDC output over current fault)";
CM_ SG_ 1107 CCU3_3_DCDC_HVOVP "DCDC输入过压
(DCDC input over voltage)";
CM_ SG_ 1107 CCU3_3_DCDC_HVUVP "DCDC输入欠压
(DCDC input under voltage)";
CM_ SG_ 1107 CCU3_3_DCDC_CANTimeOut "DCDC通讯超时
(DCDC CAN communication time-out)";
CM_ SG_ 1107 CCU3_3_DCDC_CoolRqt "DCDC冷却请求
(DCDC cool request)";
CM_ SG_ 1107 CCU3_3_DCDC_ConvMode "DCDC功率转换模式
(DCDC power conversion mode)";
CM_ SG_ 1024 VCU_0_Rsvd1 "Reserved,all value keep 0.";
CM_ SG_ 1024 VCU_0_DCDCVoutSet "DCDC输出电压设置
(DCDC output voltage point setting)";
CM_ SG_ 1024 VCU_0_Rsvd0 "Reserved,all value keep 0.";
CM_ SG_ 1024 VCU_0_DCDCEnable "DCDC输出使能请求
(DCDC output enable command)";
CM_ SG_ 1025 VCU_1_Rsvd1 "Reserved,all value keep 0.";
CM_ SG_ 1025 VCU_1_DCDCVoutSet "DCDC输出电压设置
(DCDC output voltage point setting)";
CM_ SG_ 1025 VCU_1_Rsvd0 "Reserved,all value keep 0.";
CM_ SG_ 1025 VCU_1_DCDCEnable "DCDC输出使能请求
(DCDC output enable command)";
CM_ SG_ 1026 VCU_2_Rsvd1 "Reserved,all value keep 0.";
CM_ SG_ 1026 VCU_2_DCDCVoutSet "DCDC输出电压设置
(DCDC output voltage point setting)";
CM_ SG_ 1026 VCU_2_Rsvd0 "Reserved,all value keep 0.";
CM_ SG_ 1026 VCU_2_DCDCEnable "DCDC输出使能请求
(DCDC output enable command)";
CM_ SG_ 1027 VCU_3_Rsvd1 "Reserved,all value keep 0.";
CM_ SG_ 1027 VCU_3_DCDCVoutSet "DCDC输出电压设置
(DCDC output voltage point setting)";
CM_ SG_ 1027 VCU_3_Rsvd0 "Reserved,all value keep 0.";
CM_ SG_ 1027 VCU_3_DCDCEnable "DCDC输出使能请求
(DCDC output enable command)";
CM_ SG_ 1072 CCU1_0_OBCSts "OBC工作状态
(OBC work status)";
CM_ SG_ 1072 CCU1_0_FaultLvl "充电机故障等级
(OBC fault level)";
CM_ SG_ 1072 CCU1_0_ChgCurr "充电机输出电流
(OBC output current)";
CM_ SG_ 1072 CCU1_0_ChgVolt "充电机输出电压
(OBC output voltage)";
CM_ SG_ 1072 CCU1_0_HV_UVP "充电机高压直流欠压
(OBC output under voltage)";
CM_ SG_ 1072 CCU1_0_HV_OVP "充电机高压直流过压
(OBC output over voltage)";
CM_ SG_ 1072 CCU1_0_AC_UVP "充电机交流输入欠压
(OBC input under voltage)";
CM_ SG_ 1072 CCU1_0_AC_OVP "充电机交流输入过压
(OBC input over voltage)";
CM_ SG_ 1072 CCU1_0_LV_UVP "12V低压端口欠压
(OBC KL30 under voltage)";
CM_ SG_ 1072 CCU1_0_LV_OVP "12V低压端口过压
(OBC KL30 over voltage)";
CM_ SG_ 1072 CCU1_0_HV_OCP "充电机高压直流过流
(OBC output over current)";
CM_ SG_ 1072 CCU1_0_CAN_Fault "CCU的CAN通讯故障
(CCU CAN communiction time-out)";
CM_ SG_ 1072 CCU1_0_DCAC_DTC "DCAC故障码
(DCAC_DTC)";
CM_ SG_ 1072 CCU1_0_OBC_DTC "OBC故障码
(OBC_DTC)";
CM_ SG_ 1073 CCU1_1_OBCSts "OBC工作状态
(OBC work status)";
CM_ SG_ 1073 CCU1_1_FaultLvl "充电机故障等级
(OBC fault level)";
CM_ SG_ 1073 CCU1_1_ChgCurr "充电机输出电流
(OBC output current)";
CM_ SG_ 1073 CCU1_1_ChgVolt "充电机输出电压
(OBC output voltage)";
CM_ SG_ 1073 CCU1_1_HV_UVP "充电机高压直流欠压
(OBC output under voltage)";
CM_ SG_ 1073 CCU1_1_HV_OVP "充电机高压直流过压
(OBC output over voltage)";
CM_ SG_ 1073 CCU1_1_AC_UVP "充电机交流输入欠压
(OBC input under voltage)";
CM_ SG_ 1073 CCU1_1_AC_OVP "充电机交流输入过压
(OBC input over voltage)";
CM_ SG_ 1073 CCU1_1_LV_UVP "12V低压端口欠压
(OBC KL30 under voltage)";
CM_ SG_ 1073 CCU1_1_LV_OVP "12V低压端口过压
(OBC KL30 over voltage)";
CM_ SG_ 1073 CCU1_1_HV_OCP "充电机高压直流过流
(OBC output over current)";
CM_ SG_ 1073 CCU1_1_CAN_Fault "CCU的CAN通讯故障
(CCU CAN communiction time-out)";
CM_ SG_ 1073 CCU1_1_DCAC_DTC "DCAC故障码
(DCAC_DTC)";
CM_ SG_ 1073 CCU1_1_OBC_DTC "OBC故障码
(OBC_DTC)";
CM_ SG_ 1074 CCU1_2_OBCSts "OBC工作状态
(OBC work status)";
CM_ SG_ 1074 CCU1_2_FaultLvl "充电机故障等级
(OBC fault level)";
CM_ SG_ 1074 CCU1_2_ChgCurr "充电机输出电流
(OBC output current)";
CM_ SG_ 1074 CCU1_2_ChgVolt "充电机输出电压
(OBC output voltage)";
CM_ SG_ 1074 CCU1_2_HV_UVP "充电机高压直流欠压
(OBC output under voltage)";
CM_ SG_ 1074 CCU1_2_HV_OVP "充电机高压直流过压
(OBC output over voltage)";
CM_ SG_ 1074 CCU1_2_AC_UVP "充电机交流输入欠压
(OBC input under voltage)";
CM_ SG_ 1074 CCU1_2_AC_OVP "充电机交流输入过压
(OBC input over voltage)";
CM_ SG_ 1074 CCU1_2_LV_UVP "12V低压端口欠压
(OBC KL30 under voltage)";
CM_ SG_ 1074 CCU1_2_LV_OVP "12V低压端口过压
(OBC KL30 over voltage)";
CM_ SG_ 1074 CCU1_2_HV_OCP "充电机高压直流过流
(OBC output over current)";
CM_ SG_ 1074 CCU1_2_CAN_Fault "CCU的CAN通讯故障
(CCU CAN communiction time-out)";
CM_ SG_ 1074 CCU1_2_DCAC_DTC "DCAC故障码
(DCAC_DTC)";
CM_ SG_ 1074 CCU1_2_OBC_DTC "OBC故障码
(OBC_DTC)";
CM_ SG_ 1075 CCU1_3_OBCSts "OBC工作状态
(OBC work status)";
CM_ SG_ 1075 CCU1_3_FaultLvl "充电机故障等级
(OBC fault level)";
CM_ SG_ 1075 CCU1_3_ChgCurr "充电机输出电流
(OBC output current)";
CM_ SG_ 1075 CCU1_3_ChgVolt "充电机输出电压
(OBC output voltage)";
CM_ SG_ 1075 CCU1_3_HV_UVP "充电机高压直流欠压
(OBC output under voltage)";
CM_ SG_ 1075 CCU1_3_HV_OVP "充电机高压直流过压
(OBC output over voltage)";
CM_ SG_ 1075 CCU1_3_AC_UVP "充电机交流输入欠压
(OBC input under voltage)";
CM_ SG_ 1075 CCU1_3_AC_OVP "充电机交流输入过压
(OBC input over voltage)";
CM_ SG_ 1075 CCU1_3_LV_UVP "12V低压端口欠压
(OBC KL30 under voltage)";
CM_ SG_ 1075 CCU1_3_LV_OVP "12V低压端口过压
(OBC KL30 over voltage)";
CM_ SG_ 1075 CCU1_3_HV_OCP "充电机高压直流过流
(OBC output over current)";
CM_ SG_ 1075 CCU1_3_CAN_Fault "CCU的CAN通讯故障
(CCU CAN communiction time-out)";
CM_ SG_ 1075 CCU1_3_DCAC_DTC "DCAC故障码
(DCAC_DTC)";
CM_ SG_ 1075 CCU1_3_OBC_DTC "OBC故障码
(OBC_DTC)";
CM_ BO_ 1280 "Event";
CM_ BO_ 1281 "Event";
CM_ BO_ 1282 "Event";
CM_ BO_ 1283 "Event";
CM_ BO_ 1296 "Event";
CM_ BO_ 1297 "Event";
CM_ BO_ 1298 "Event";
CM_ BO_ 1299 "Event";
BA_DEF_  "BusType" STRING ;
BA_DEF_ BO_  "GenMsgCycleTime" INT 0 65535;
BA_DEF_ SG_  "GenSigStartValue" FLOAT -3.4E+038 3.4E+038;
BA_DEF_DEF_  "BusType" "CAN";
BA_DEF_DEF_  "GenMsgCycleTime" 0;
BA_DEF_DEF_  "GenSigStartValue" 0;
BA_ "GenMsgCycleTime" BO_ 1088 500;
BA_ "GenMsgCycleTime" BO_ 1089 500;
BA_ "GenMsgCycleTime" BO_ 1090 500;
BA_ "GenMsgCycleTime" BO_ 1091 500;
BA_ "GenMsgCycleTime" BO_ 1056 500;
BA_ "GenMsgCycleTime" BO_ 1057 500;
BA_ "GenMsgCycleTime" BO_ 1058 500;
BA_ "GenMsgCycleTime" BO_ 1059 500;
BA_ "GenMsgCycleTime" BO_ 1104 10;
BA_ "GenMsgCycleTime" BO_ 1105 10;
BA_ "GenMsgCycleTime" BO_ 1106 10;
BA_ "GenMsgCycleTime" BO_ 1107 10;
BA_ "GenMsgCycleTime" BO_ 1024 100;
BA_ "GenMsgCycleTime" BO_ 1025 100;
BA_ "GenMsgCycleTime" BO_ 1026 100;
BA_ "GenMsgCycleTime" BO_ 1027 100;
BA_ "GenMsgCycleTime" BO_ 1072 500;
BA_ "GenMsgCycleTime" BO_ 1073 500;
BA_ "GenMsgCycleTime" BO_ 1074 500;
BA_ "GenMsgCycleTime" BO_ 1075 500;
BA_ "GenSigStartValue" SG_ 1088 CCU2_0_TempChg 40;
BA_ "GenSigStartValue" SG_ 1088 CCU2_0_AC_Volt 40;
BA_ "GenSigStartValue" SG_ 1089 CCU2_1_TempChg 40;
BA_ "GenSigStartValue" SG_ 1089 CCU2_1_AC_Volt 40;
BA_ "GenSigStartValue" SG_ 1090 CCU2_2_TempChg 40;
BA_ "GenSigStartValue" SG_ 1090 CCU2_2_AC_Volt 40;
BA_ "GenSigStartValue" SG_ 1091 CCU2_3_TempChg 40;
BA_ "GenSigStartValue" SG_ 1091 CCU2_3_AC_Volt 40;
BA_ "GenSigStartValue" SG_ 1056 BMS_0_OBC_CurrReq 200;
BA_ "GenSigStartValue" SG_ 1056 BMS_0_OBC_VoltReq 7000;
BA_ "GenSigStartValue" SG_ 1057 BMS_1_OBC_CurrReq 200;
BA_ "GenSigStartValue" SG_ 1057 BMS_1_OBC_VoltReq 7000;
BA_ "GenSigStartValue" SG_ 1058 BMS_2_OBC_CurrReq 200;
BA_ "GenSigStartValue" SG_ 1058 BMS_2_OBC_VoltReq 7000;
BA_ "GenSigStartValue" SG_ 1059 BMS_3_OBC_CurrReq 200;
BA_ "GenSigStartValue" SG_ 1059 BMS_3_OBC_VoltReq 7000;
VAL_ 1088 CCU2_0_DCAC_FaultLvl 3 "Level3 fault" 2 "Level2 fault" 1 "Level1 fault" 0 "No fault" ;
VAL_ 1088 CCU2_0_DCAC_WorkSts 0 "No charge" 1 "Ready" 2 "DCharging" 3 "DCharge finished" ;
VAL_ 1088 CCU2_0_DCAC_CCSts 0 "CC_UnConnect" 1 "CC_Connect" 2 "CC_HalfConnect" ;
VAL_ 1088 CCU2_0_S2Sts 0 "open" 1 "closed" ;
VAL_ 1088 CCU2_0_OBC_CCSts 0 "CC_UnConnect" 1 "CC_Connect" 2 "CC_HalfConnect" ;
VAL_ 1088 CCU2_0_ChgOTPFaultLvl 0 "Normal" 1 "Over_Tempe_1_level" 2 "Over_Tempe_2_level" ;
VAL_ 1088 CCU2_0_CoolingReq 0 "No_request" 1 "Cool_request" ;
VAL_ 1088 CCU2_0_VersionNo 0 "Default" 1 "C1" 2 "C2" 3 "C3" ;
VAL_ 1088 CCU2_0_CP_DutyFault 0 "Normal" 1 "CP_duty_fault" ;
VAL_ 1088 CCU2_0_CPState 0 "CP_UnConnect" 1 "CP_3V" 2 "CP_3VPWM" 3 "CP_6V" 4 "CP_6VPWM" 5 "CP_9V" 6 "CP_9VPWM" 7 "CP_12V" 8 "CP_12VPWM" 15 "CP_OutOfRange" ;
VAL_ 1089 CCU2_1_DCAC_FaultLvl 3 "Level3 fault" 2 "Level2 fault" 1 "Level1 fault" 0 "No fault" ;
VAL_ 1089 CCU2_1_DCAC_WorkSts 0 "No charge" 1 "Ready" 2 "DCharging" 3 "DCharge finished" ;
VAL_ 1089 CCU2_1_DCAC_CCSts 0 "CC_UnConnect" 1 "CC_Connect" 2 "CC_HalfConnect" ;
VAL_ 1089 CCU2_1_S2Sts 0 "open" 1 "closed" ;
VAL_ 1089 CCU2_1_OBC_CCSts 0 "CC_UnConnect" 1 "CC_Connect" 2 "CC_HalfConnect" ;
VAL_ 1089 CCU2_1_ChgOTPFaultLvl 0 "Normal" 1 "Over_Tempe_1_level" 2 "Over_Tempe_2_level" ;
VAL_ 1089 CCU2_1_CoolingReq 0 "No_request" 1 "Cool_request" ;
VAL_ 1089 CCU2_1_VersionNo 0 "default" 1 "C1" 2 "C2" 3 "C3" ;
VAL_ 1089 CCU2_1_CP_DutyFault 0 "Normal" 1 "CP_duty_fault" ;
VAL_ 1089 CCU2_1_CPState 0 "CP_UnConnect" 1 "CP_3V" 2 "CP_3VPWM" 3 "CP_6V" 4 "CP_6VPWM" 5 "CP_9V" 6 "CP_9VPWM" 7 "CP_12V" 8 "CP_12VPWM" 15 "CP_OutOfRange" ;
VAL_ 1090 CCU2_2_DCAC_FaultLvl 3 "Level3 fault" 2 "Level2 fault" 1 "Level1 fault" 0 "No fault" ;
VAL_ 1090 CCU2_2_DCAC_WorkSts 0 "No charge" 1 "Ready" 2 "DCharging" 3 "DCharge finished" ;
VAL_ 1090 CCU2_2_DCAC_CCSts 0 "CC_UnConnect" 1 "CC_Connect" 2 "CC_HalfConnect" ;
VAL_ 1090 CCU2_2_S2Sts 0 "open" 1 "closed" ;
VAL_ 1090 CCU2_2_OBC_CCSts 0 "CC_UnConnect" 1 "CC_Connect" 2 "CC_HalfConnect" ;
VAL_ 1090 CCU2_2_ChgOTPFaultLvl 0 "Normal" 1 "Over_Tempe_1_level" 2 "Over_Tempe_2_level" ;
VAL_ 1090 CCU2_2_CoolingReq 0 "No_request" 1 "Cool_request" ;
VAL_ 1090 CCU2_2_VersionNo 0 "Default" 1 "C1" 2 "C2" 3 "C3" ;
VAL_ 1090 CCU2_2_CP_DutyFault 0 "Normal" 1 "CP_duty_fault" ;
VAL_ 1090 CCU2_2_CPState 0 "CP_UnConnect" 1 "CP_3V" 2 "CP_3VPWM" 3 "CP_6V" 4 "CP_6VPWM" 5 "CP_9V" 6 "CP_9VPWM" 7 "CP_12V" 8 "CP_12VPWM" 15 "CP_OutOfRange" ;
VAL_ 1091 CCU2_3_DCAC_FaultLvl 3 "Level3 fault" 2 "Level2 fault" 1 "Level1 fault" 0 "No fault" ;
VAL_ 1091 CCU2_3_DCAC_WorkSts 0 "No charge" 1 "Ready" 2 "DCharging" 3 "DCharge finished" ;
VAL_ 1091 CCU2_3_DCAC_CCSts 0 "CC_UnConnect" 1 "CC_Connect" 2 "CC_HalfConnect" ;
VAL_ 1091 CCU2_3_S2Sts 0 "open" 1 "closed" ;
VAL_ 1091 CCU2_3_OBC_CCSts 0 "CC_UnConnect" 1 "CC_Connect" 2 "CC_HalfConnect" ;
VAL_ 1091 CCU2_3_ChgOTPFaultLvl 0 "Normal" 1 "Over_Tempe_1_level" 2 "Over_Tempe_2_level" ;
VAL_ 1091 CCU2_3_CoolingReq 0 "No_request" 1 "Cool_request" ;
VAL_ 1091 CCU2_3_VersionNo 0 "Default" 1 "C1" 2 "C2" 3 "C3" ;
VAL_ 1091 CCU2_3_CP_DutyFault 0 "Normal" 1 "CP_duty_fault" ;
VAL_ 1091 CCU2_3_CPState 0 "CP_UnConnect" 1 "CP_3V" 2 "CP_3VPWM" 3 "CP_6V" 4 "CP_6VPWM" 5 "CP_9V" 6 "CP_9VPWM" 7 "CP_12V" 8 "CP_12VPWM" 15 "CP_OutOfRange" ;
VAL_ 1056 BMS_0_OBC_WorkModReq 0 "Disconnect" 1 "Charge" 2 "Heat" 3 "Precharge" 4 "Discharge" ;
VAL_ 1056 BMS_0_LVOutDisable 0 "Output Enable" 1 "Output Disable" ;
VAL_ 1056 BMS_0_CPState 0 "CP_UnConnect" 1 "CP_3V" 2 "CP_3VPWM" 3 "CP_6V" 4 "CP_6VPWM" 5 "CP_9V" 6 "CP_9VPWM" 7 "CP_12V" 8 "CP_12VPWM" 15 "CP_OutOfRange" ;
VAL_ 1056 BMS_0_CCState 0 "CC_UnConnect" 1 "CC_HalfConnect" 2 "CC_Connect" ;
VAL_ 1056 BMS_0_DCAC_EnReq 0 "Inactive/Initial value" 1 "Disable" 2 "Enable" ;
VAL_ 1057 BMS_1_OBC_WorkModReq 0 "Disconnect" 1 "Charge" 2 "Heat" 3 "Precharge" 4 "Discharge" ;
VAL_ 1057 BMS_1_LVOutDisable 0 "Output Enable" 1 "Output Disable" ;
VAL_ 1057 BMS_1_CPState 0 "CP_UnConnect" 1 "CP_3V" 2 "CP_3VPWM" 3 "CP_6V" 4 "CP_6VPWM" 5 "CP_9V" 6 "CP_9VPWM" 7 "CP_12V" 8 "CP_12VPWM" 15 "CP_OutOfRange" ;
VAL_ 1057 BMS_1_CCState 0 "CC_UnConnect" 1 "CC_HalfConnect" 2 "CC_Connect" ;
VAL_ 1057 BMS_1_DCAC_EnReq 0 "Inactive/Initial value" 1 "Disable" 2 "Enable" ;
VAL_ 1058 BMS_2_OBC_WorkModReq 0 "Disconnect" 1 "Charge" 2 "Heat" 3 "Precharge" 4 "Discharge" ;
VAL_ 1058 BMS_2_LVOutDisable 0 "Output Enable" 1 "Output Disable" ;
VAL_ 1058 BMS_2_CPState 0 "CP_UnConnect" 1 "CP_3V" 2 "CP_3VPWM" 3 "CP_6V" 4 "CP_6VPWM" 5 "CP_9V" 6 "CP_9VPWM" 7 "CP_12V" 8 "CP_12VPWM" 15 "CP_OutOfRange" ;
VAL_ 1058 BMS_2_CCState 0 "CC_UnConnect" 1 "CC_HalfConnect" 2 "CC_Connect" ;
VAL_ 1058 BMS_2_DCAC_EnReq 0 "Inactive/Initial value" 1 "Disable" 2 "Enable" ;
VAL_ 1059 BMS_3_OBC_WorkModReq 0 "Disconnect" 1 "Charge" 2 "Heat" 3 "Precharge" 4 "Discharge" ;
VAL_ 1059 BMS_3_LVOutDisable 0 "Output Enable" 1 "Output Disable" ;
VAL_ 1059 BMS_3_CPState 0 "CP_UnConnect" 1 "CP_3V" 2 "CP_3VPWM" 3 "CP_6V" 4 "CP_6VPWM" 5 "CP_9V" 6 "CP_9VPWM" 7 "CP_12V" 8 "CP_12VPWM" 15 "CP_OutOfRange" ;
VAL_ 1059 BMS_3_CCState 0 "CC_UnConnect" 1 "CC_HalfConnect" 2 "CC_Connect" ;
VAL_ 1059 BMS_3_DCAC_EnReq 0 "Inactive/Initial value" 1 "Disable" 2 "Enable" ;
VAL_ 1104 CCU3_0_DCDC_WorkSts 0 "Standby" 1 "Buck" 2 "Failure" 3 "Reserved" ;
VAL_ 1104 CCU3_0_DCDC_EnSts 0 "Disable" 1 "Enable" ;
VAL_ 1104 CCU3_0_DCDC_DTC 0 "No Fault" 1 "RSVD1" 2 "ACUVP" 3 "RSVD3" 4 "HVUVP" 5 "HVOVP" 6 "HVOCP " 7 "HWOCP" 8 "LVIoFbOpen" 9 "LVVoFbOpen" 10 "PFCOVP" 11 "LVOCP" 12 "VinOVP" 13 "VinUVP" 14 "Inn1CommuErr" 15 "Inn0CommuErr" 16 "RSVD16" 17 "LVOVP" 18 "DCDCOTP" 19 "TempSenseErr" 255 "RSVD255" ;
VAL_ 1104 CCU3_0_DCDC_LVOVP 0 "NoFault" 1 "Fault" ;
VAL_ 1104 CCU3_0_DCDC_LVUVP 0 "NoFault" 1 "Fault" ;
VAL_ 1104 CCU3_0_DCDC_OTP 0 "NoFault" 1 "Fault" ;
VAL_ 1104 CCU3_0_DCDC_LVOCP 0 "NoFault" 1 "Fault" ;
VAL_ 1104 CCU3_0_DCDC_HVOVP 0 "NoFault" 1 "Fault" ;
VAL_ 1104 CCU3_0_DCDC_HVUVP 0 "NoFault" 1 "Fault" ;
VAL_ 1104 CCU3_0_DCDC_CANTimeOut 0 "NoFault" 1 "Fault" ;
VAL_ 1104 CCU3_0_DCDC_CoolRqt 0 "NoCoolingRqt" 1 "CoolingRqt" ;
VAL_ 1104 CCU3_0_DCDC_ConvMode 0 "HV_LV" 1 "AC_LV" 2 "Rsvd0" 3 "Rsvd1" ;
VAL_ 1105 CCU3_1_DCDC_WorkSts 0 "Standby" 1 "Buck" 2 "Failure" 3 "Reserved" ;
VAL_ 1105 CCU3_1_DCDC_EnSts 0 "Disable" 1 "Enable" ;
VAL_ 1105 CCU3_1_DCDC_DTC 0 "No Fault" 1 "RSVD1" 2 "ACUVP" 3 "RSVD3" 4 "HVUVP" 5 "HVOVP" 6 "HVOCP " 7 "HWOCP" 8 "LVIoFbOpen" 9 "LVVoFbOpen" 10 "PFCOVP" 11 "LVOCP" 12 "VinOVP" 13 "VinUVP" 14 "Inn1CommuErr" 15 "Inn0CommuErr" 16 "RSVD16" 17 "LVOVP" 18 "DCDCOTP" 19 "TempSenseErr" 255 "RSVD255" ;
VAL_ 1105 CCU3_1_DCDC_LVOVP 0 "NoFault" 1 "Fault" ;
VAL_ 1105 CCU3_1_DCDC_LVUVP 0 "NoFault" 1 "Fault" ;
VAL_ 1105 CCU3_1_DCDC_OTP 0 "NoFault" 1 "Fault" ;
VAL_ 1105 CCU3_1_DCDC_LVOCP 0 "NoFault" 1 "Fault" ;
VAL_ 1105 CCU3_1_DCDC_HVOVP 0 "NoFault" 1 "Fault" ;
VAL_ 1105 CCU3_1_DCDC_HVUVP 0 "NoFault" 1 "Fault" ;
VAL_ 1105 CCU3_1_DCDC_CANTimeOut 0 "NoFault" 1 "Fault" ;
VAL_ 1105 CCU3_1_DCDC_CoolRqt 0 "NoCoolingRqt" 1 "CoolingRqt" ;
VAL_ 1105 CCU3_1_DCDC_ConvMode 0 "HV_LV" 1 "AC_LV" 2 "Rsvd0" 3 "Rsvd1" ;
VAL_ 1106 CCU3_2_DCDC_WorkSts 0 "Standby" 1 "Buck" 2 "Failure" 3 "Reserved" ;
VAL_ 1106 CCU3_2_DCDC_EnSts 0 "Disable" 1 "Enable" ;
VAL_ 1106 CCU3_2_DCDC_DTC 0 "No Fault" 1 "RSVD1" 2 "ACUVP" 3 "RSVD3" 4 "HVUVP" 5 "HVOVP" 6 "HVOCP " 7 "HWOCP" 8 "LVIoFbOpen" 9 "LVVoFbOpen" 10 "PFCOVP" 11 "LVOCP" 12 "VinOVP" 13 "VinUVP" 14 "Inn1CommuErr" 15 "Inn0CommuErr" 16 "RSVD16" 17 "LVOVP" 18 "DCDCOTP" 19 "TempSenseErr" 255 "RSVD255" ;
VAL_ 1106 CCU3_2_DCDC_LVOVP 0 "NoFault" 1 "Fault" ;
VAL_ 1106 CCU3_2_DCDC_LVUVP 0 "NoFault" 1 "Fault" ;
VAL_ 1106 CCU3_2_DCDC_OTP 0 "NoFault" 1 "Fault" ;
VAL_ 1106 CCU3_2_DCDC_LVOCP 0 "NoFault" 1 "Fault" ;
VAL_ 1106 CCU3_2_DCDC_HVOVP 0 "NoFault" 1 "Fault" ;
VAL_ 1106 CCU3_2_DCDC_HVUVP 0 "NoFault" 1 "Fault" ;
VAL_ 1106 CCU3_2_DCDC_CANTimeOut 0 "NoFault" 1 "Fault" ;
VAL_ 1106 CCU3_2_DCDC_CoolRqt 0 "NoCoolingRqt" 1 "CoolingRqt" ;
VAL_ 1106 CCU3_2_DCDC_ConvMode 0 "HV_LV" 1 "AC_LV" 2 "Rsvd0" 3 "Rsvd1" ;
VAL_ 1107 CCU3_3_DCDC_WorkSts 0 "Standby" 1 "Buck" 2 "Failure" 3 "Reserved" ;
VAL_ 1107 CCU3_3_DCDC_EnSts 0 "Disable" 1 "Enable" ;
VAL_ 1107 CCU3_3_DCDC_DTC 0 "No Fault" 1 "RSVD1" 2 "ACUVP" 3 "RSVD3" 4 "HVUVP" 5 "HVOVP" 6 "HVOCP " 7 "HWOCP" 8 "LVIoFbOpen" 9 "LVVoFbOpen" 10 "PFCOVP" 11 "LVOCP" 12 "VinOVP" 13 "VinUVP" 14 "Inn1CommuErr" 15 "Inn0CommuErr" 16 "RSVD16" 17 "LVOVP" 18 "DCDCOTP" 19 "TempSenseErr" 255 "RSVD255" ;
VAL_ 1107 CCU3_3_DCDC_LVOVP 0 "NoFault" 1 "Fault" ;
VAL_ 1107 CCU3_3_DCDC_LVUVP 0 "NoFault" 1 "Fault" ;
VAL_ 1107 CCU3_3_DCDC_OTP 0 "NoFault" 1 "Fault" ;
VAL_ 1107 CCU3_3_DCDC_LVOCP 0 "NoFault" 1 "Fault" ;
VAL_ 1107 CCU3_3_DCDC_HVOVP 0 "NoFault" 1 "Fault" ;
VAL_ 1107 CCU3_3_DCDC_HVUVP 0 "NoFault" 1 "Fault" ;
VAL_ 1107 CCU3_3_DCDC_CANTimeOut 0 "NoFault" 1 "Fault" ;
VAL_ 1107 CCU3_3_DCDC_CoolRqt 0 "NoCoolingRqt" 1 "CoolingRqt" ;
VAL_ 1107 CCU3_3_DCDC_ConvMode 0 "HV_LV" 1 "AC_LV" 2 "Rsvd0" 3 "Rsvd1" ;
VAL_ 1024 VCU_0_DCDCEnable 0 "Disable" 1 "Enable" ;
VAL_ 1025 VCU_1_DCDCEnable 0 "Disable" 1 "Enable" ;
VAL_ 1026 VCU_2_DCDCEnable 0 "Disable" 1 "Enable" ;
VAL_ 1027 VCU_3_DCDCEnable 0 "Disable" 1 "Enable" ;
VAL_ 1072 CCU1_0_OBCSts 0 "No charge" 1 "Ready" 2 "Charging" 3 "Charge finished" 4 "Heating" 5 "Charging pause" ;
VAL_ 1072 CCU1_0_FaultLvl 0 "No fault" 1 "Level1 fault" 2 "Level2 fault" 3 "Level2 fault" ;
VAL_ 1072 CCU1_0_HV_UVP 0 "No fault" 1 "Fault" ;
VAL_ 1072 CCU1_0_HV_OVP 0 "No fault" 1 "Fault" ;
VAL_ 1072 CCU1_0_AC_UVP 0 "No fault" 1 "Fault" ;
VAL_ 1072 CCU1_0_AC_OVP 0 "No fault" 1 "Fault" ;
VAL_ 1072 CCU1_0_LV_UVP 0 "No fault" 1 "Fault" ;
VAL_ 1072 CCU1_0_LV_OVP 0 "No fault" 1 "Fault" ;
VAL_ 1072 CCU1_0_HV_OCP 0 "No fault" 1 "Fault" ;
VAL_ 1072 CCU1_0_CAN_Fault 0 "No fault" 1 "Fault" ;
VAL_ 1072 CCU1_0_DCAC_DTC 0 "NO Fault" 1 "TempSenseErr" 2 "InsulationFault" 3 "LVOVP" 4 "PFCOCP " 5 "LVUVP" 6 "VinOVP" 7 "VinUVP" 8 "PFCOVP" 9 "ACOVP" 10 "CCUnValid" 11 "Inn1CommuErr" 12 "Inn2CommuErr" 13 "AirUTP" 14 "HWOCP" 15 "AIROTP" 16 "Cali2Err" 17 "Cali1Err" 18 "BMSCANTimeOut" 255 "RSVD255" ;
VAL_ 1072 CCU1_0_OBC_DTC 0 "NO Fault" 1 "RSVD1" 2 "TempDerate" 3 "TempSenseErr" 4 "RSVD4" 5 "LVOVP" 6 "PFCOCP" 7 "LVUVP" 8 "HVOVP" 9 "HVUVP" 10 "PFCOVP" 11 "ACOVP" 12 "ACUVP" 13 "ACOFF" 14 "Inn1CommuErr" 15 "Inn2CommuErr" 16 "CPUnValid" 17 "CCUnValid" 18 "AirUTP" 19 "KL31OVP" 20 "WakeUpShort" 21 "HWOCP" 22 "OBCOTP" 23 "Cali2Err" 24 "Cali1Err" 25 "BMSCANTimeOut" 255 "RSVD255" ;
VAL_ 1073 CCU1_1_OBCSts 0 "No charge" 1 "Ready" 2 "Charging" 3 "Charge finished" 4 "Heating" 5 "Charging pause" ;
VAL_ 1073 CCU1_1_FaultLvl 0 "No fault" 1 "Level1 fault" 2 "Level2 fault" 3 "Level2 fault" ;
VAL_ 1073 CCU1_1_HV_UVP 0 "No fault" 1 "Fault" ;
VAL_ 1073 CCU1_1_HV_OVP 0 "No fault" 1 "Fault" ;
VAL_ 1073 CCU1_1_AC_UVP 0 "No fault" 1 "Fault" ;
VAL_ 1073 CCU1_1_AC_OVP 0 "No fault" 1 "Fault" ;
VAL_ 1073 CCU1_1_LV_UVP 0 "No fault" 1 "Fault" ;
VAL_ 1073 CCU1_1_LV_OVP 0 "No fault" 1 "Fault" ;
VAL_ 1073 CCU1_1_HV_OCP 0 "No fault" 1 "Fault" ;
VAL_ 1073 CCU1_1_CAN_Fault 0 "No fault" 1 "Fault" ;
VAL_ 1073 CCU1_1_DCAC_DTC 0 "NO Fault" 1 "TempSenseErr" 2 "InsulationFault" 3 "LVOVP" 4 "PFCOCP " 5 "LVUVP" 6 "VinOVP" 7 "VinUVP" 8 "PFCOVP" 9 "ACOVP" 10 "CCUnValid" 11 "Inn1CommuErr" 12 "Inn2CommuErr" 13 "AirUTP" 14 "HWOCP" 15 "AIROTP" 16 "Cali2Err" 17 "Cali1Err" 18 "BMSCANTimeOut" 255 "RSVD255" ;
VAL_ 1073 CCU1_1_OBC_DTC 0 "NO Fault" 1 "RSVD1" 2 "TempDerate" 3 "TempSenseErr" 4 "RSVD4" 5 "LVOVP" 6 "PFCOCP" 7 "LVUVP" 8 "HVOVP" 9 "HVUVP" 10 "PFCOVP" 11 "ACOVP" 12 "ACUVP" 13 "ACOFF" 14 "Inn1CommuErr" 15 "Inn2CommuErr" 16 "CPUnValid" 17 "CCUnValid" 18 "AirUTP" 19 "KL31OVP" 20 "WakeUpShort" 21 "HWOCP" 22 "OBCOTP" 23 "Cali2Err" 24 "Cali1Err" 25 "BMSCANTimeOut" 255 "RSVD255" ;
VAL_ 1074 CCU1_2_OBCSts 0 "No charge" 1 "Ready" 2 "Charging" 3 "Charge finished" 4 "Heating" 5 "Charging pause" ;
VAL_ 1074 CCU1_2_FaultLvl 0 "No fault" 1 "Level1 fault" 2 "Level2 fault" 3 "Level2 fault" ;
VAL_ 1074 CCU1_2_HV_UVP 0 "No fault" 1 "Fault" ;
VAL_ 1074 CCU1_2_HV_OVP 0 "No fault" 1 "Fault" ;
VAL_ 1074 CCU1_2_AC_UVP 0 "No fault" 1 "Fault" ;
VAL_ 1074 CCU1_2_AC_OVP 0 "No fault" 1 "Fault" ;
VAL_ 1074 CCU1_2_LV_UVP 0 "No fault" 1 "Fault" ;
VAL_ 1074 CCU1_2_LV_OVP 0 "No fault" 1 "Fault" ;
VAL_ 1074 CCU1_2_HV_OCP 0 "No fault" 1 "Fault" ;
VAL_ 1074 CCU1_2_CAN_Fault 0 "No fault" 1 "Fault" ;
VAL_ 1074 CCU1_2_DCAC_DTC 0 "NO Fault" 1 "TempSenseErr" 2 "InsulationFault" 3 "LVOVP" 4 "PFCOCP " 5 "LVUVP" 6 "VinOVP" 7 "VinUVP" 8 "PFCOVP" 9 "ACOVP" 10 "CCUnValid" 11 "Inn1CommuErr" 12 "Inn2CommuErr" 13 "AirUTP" 14 "HWOCP" 15 "AIROTP" 16 "Cali2Err" 17 "Cali1Err" 18 "BMSCANTimeOut" 255 "RSVD255" ;
VAL_ 1074 CCU1_2_OBC_DTC 0 "NO Fault" 1 "RSVD1" 2 "TempDerate" 3 "TempSenseErr" 4 "RSVD4" 5 "LVOVP" 6 "PFCOCP" 7 "LVUVP" 8 "HVOVP" 9 "HVUVP" 10 "PFCOVP" 11 "ACOVP" 12 "ACUVP" 13 "ACOFF" 14 "Inn1CommuErr" 15 "Inn2CommuErr" 16 "CPUnValid" 17 "CCUnValid" 18 "AirUTP" 19 "KL31OVP" 20 "WakeUpShort" 21 "HWOCP" 22 "OBCOTP" 23 "Cali2Err" 24 "Cali1Err" 25 "BMSCANTimeOut" 255 "RSVD255" ;
VAL_ 1075 CCU1_3_OBCSts 0 "No charge" 1 "Ready" 2 "Charging" 3 "Charge finished" 4 "Heating" 5 "Charging pause" ;
VAL_ 1075 CCU1_3_FaultLvl 0 "No fault" 1 "Level1 fault" 2 "Level2 fault" 3 "Level2 fault" ;
VAL_ 1075 CCU1_3_HV_UVP 0 "No fault" 1 "Fault" ;
VAL_ 1075 CCU1_3_HV_OVP 0 "No fault" 1 "Fault" ;
VAL_ 1075 CCU1_3_AC_UVP 0 "No fault" 1 "Fault" ;
VAL_ 1075 CCU1_3_AC_OVP 0 "No fault" 1 "Fault" ;
VAL_ 1075 CCU1_3_LV_UVP 0 "No fault" 1 "Fault" ;
VAL_ 1075 CCU1_3_LV_OVP 0 "No fault" 1 "Fault" ;
VAL_ 1075 CCU1_3_HV_OCP 0 "No fault" 1 "Fault" ;
VAL_ 1075 CCU1_3_CAN_Fault 0 "No fault" 1 "Fault" ;
VAL_ 1075 CCU1_3_DCAC_DTC 0 "NO Fault" 1 "TempSenseErr" 2 "InsulationFault" 3 "LVOVP" 4 "PFCOCP " 5 "LVUVP" 6 "VinOVP" 7 "VinUVP" 8 "PFCOVP" 9 "ACOVP" 10 "CCUnValid" 11 "Inn1CommuErr" 12 "Inn2CommuErr" 13 "AirUTP" 14 "HWOCP" 15 "AIROTP" 16 "Cali2Err" 17 "Cali1Err" 18 "BMSCANTimeOut" 255 "RSVD255" ;
VAL_ 1075 CCU1_3_OBC_DTC 0 "NO Fault" 1 "RSVD1" 2 "TempDerate" 3 "TempSenseErr" 4 "RSVD4" 5 "LVOVP" 6 "PFCOCP" 7 "LVUVP" 8 "HVOVP" 9 "HVUVP" 10 "PFCOVP" 11 "ACOVP" 12 "ACUVP" 13 "ACOFF" 14 "Inn1CommuErr" 15 "Inn2CommuErr" 16 "CPUnValid" 17 "CCUnValid" 18 "AirUTP" 19 "KL31OVP" 20 "WakeUpShort" 21 "HWOCP" 22 "OBCOTP" 23 "Cali2Err" 24 "Cali1Err" 25 "BMSCANTimeOut" 255 "RSVD255" ;
